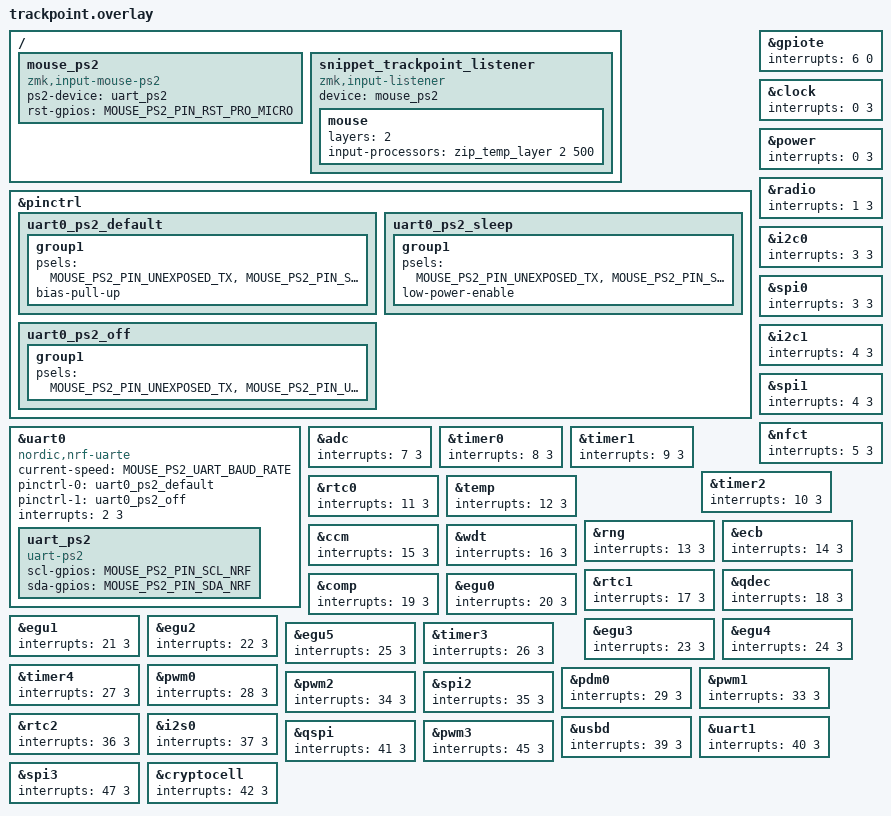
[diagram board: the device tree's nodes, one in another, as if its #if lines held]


#define MOUSE_PS2_DRIVER_UART
#define MOUSE_PS2_PIN_SCL_NRF <&gpio0 14 GPIO_ACTIVE_HIGH>
#define MOUSE_PS2_PIN_SDA_NRF <&gpio0 12 GPIO_ACTIVE_HIGH>
#define MOUSE_PS2_PIN_SDA_PINCTRL <NRF_PSEL(UART_RX, 0, 12)>
// Configure the Power-On-Reset pin

//#define MOUSE_PS2_PIN_RST_PRO_MICRO <&pro_micro 9 GPIO_ACTIVE_HIGH>

// Configure UART BAUD Rate
//
// Convert cycle length in microseconds into baud:
// 1 / PS2_CYCLE_LENGTH * 1000000 =  BAUD
// 1 / 67 * 1000000 = 14,925 BAUD
// Most trackpoints seem to operate at around 14-15kHz.
// Therefore, the most likely values to try are:
//   - 14400 ( 69 us cycle length   /   14.5kHz)
//   -  9600 (100 us cycle length   /   10.0kHz)
//   - 19200 ( 52 us cycle length   /   19kHz)
#define MOUSE_PS2_UART_BAUD_RATE <14400>

// Do NOT change these if you are using a nice!nano (or a clone of it)
#define MOUSE_PS2_PIN_UNEXPOSED_TX <NRF_PSEL(UART_TX, 0, 25)>
#define MOUSE_PS2_PIN_UNEXPOSED_RX <NRF_PSEL(UART_RX, 0, 27)>

#define MOUSE_PS2_DT_PRESENT

&pinctrl {
	uart0_ps2_default: uart0_ps2_default {
		group1 {
			psels = MOUSE_PS2_PIN_UNEXPOSED_TX,
					MOUSE_PS2_PIN_SDA_PINCTRL;
            bias-pull-up;
		};
	};

	// Set this to the same pins as uart0_ps2_default
	uart0_ps2_sleep: uart0_ps2_sleep {
		group1 {
			psels = MOUSE_PS2_PIN_UNEXPOSED_TX,
					MOUSE_PS2_PIN_SDA_PINCTRL;
			low-power-enable;
		};
	};

	uart0_ps2_off: uart0_ps2_off {
		group1 {
			psels = MOUSE_PS2_PIN_UNEXPOSED_TX,
					MOUSE_PS2_PIN_UNEXPOSED_RX;
		};
	};
};


#ifdef MOUSE_PS2_DRIVER_UART

    &uart0 {
       
        compatible = "nordic,nrf-uarte";

        current-speed = MOUSE_PS2_UART_BAUD_RATE;
        pinctrl-0 = <&uart0_ps2_default>;
        pinctrl-1 = <&uart0_ps2_off>;

        pinctrl-names = "default", "sleep";

        uart_ps2: uart_ps2 {
          
            compatible = "uart-ps2";
            scl-gpios = MOUSE_PS2_PIN_SCL_NRF;
            sda-gpios = MOUSE_PS2_PIN_SDA_NRF;
        };
    };

#else

    / {
        gpio_ps2: gpio_ps2 {
            status = "disabled";

            compatible = "gpio-ps2";
            scl-gpios = MOUSE_PS2_PIN_SCL_NRF;
            sda-gpios = MOUSE_PS2_PIN_SDA_NRF;
        };
    };

#endif


/ {
    mouse_ps2: mouse_ps2 {
        compatible = "zmk,input-mouse-ps2";
        
#ifdef MOUSE_PS2_DRIVER_UART
	    ps2-device = <&uart_ps2>;
#else
	    ps2-device = <&gpio_ps2>;
#endif

#ifdef MOUSE_PS2_PIN_RST_PRO_MICRO
        rst-gpios = MOUSE_PS2_PIN_RST_PRO_MICRO;
#endif
    };
};

/{
    snippet_trackpoint_listener: snippet_trackpoint_listener {
        compatible = "zmk,input-listener";
        device = <&mouse_ps2>;
        mouse {
            layers = <2>;
            input-processors = <&zip_temp_layer 2 500>;
        };
    };    
};

&gpiote {
    interrupts = < 6 0 >;
};

&clock {
    interrupts = < 0 3 >;
};

&power {
    interrupts = < 0 3 >;
};

&radio {
    interrupts = < 1 3 >;
};

&uart0 {
    interrupts = < 2 3 >;
};

&i2c0 {
    interrupts = < 3 3 >;
};

&spi0 {
    interrupts = < 3 3 >;
};

&i2c1 {
    interrupts = < 4 3 >;
};

&spi1 {
    interrupts = < 4 3 >;
};

&nfct {
    interrupts = < 5 3 >;
};

&adc {
    interrupts = < 7 3 >;
};

&timer0 {
    interrupts = < 8 3 >;
};

&timer1 {
    interrupts = < 9 3 >;
};

&timer2 {
    interrupts = < 10 3 >;
};

&rtc0 {
    interrupts = < 11 3 >;
};

&temp {
    interrupts = < 12 3 >;
};

&rng {
    interrupts = < 13 3 >;
};

&ecb {
    interrupts = < 14 3 >;
};

&ccm {
    interrupts = < 15 3 >;
};

&wdt {
    interrupts = < 16 3 >;
};

&rtc1 {
    interrupts = < 17 3 >;
};

&qdec {
    interrupts = < 18 3 >;
};

&comp {
    interrupts = < 19 3 >;
};

&egu0 {
    interrupts = < 20 3 >;
};

&egu1 {
    interrupts = < 21 3 >;
};

&egu2 {
    interrupts = < 22 3 >;
};

&egu3 {
    interrupts = < 23 3 >;
};

&egu4 {
    interrupts = < 24 3 >;
};

&egu5 {
    interrupts = < 25 3 >;
};

&timer3 {
    interrupts = < 26 3 >;
};

&timer4 {
    interrupts = < 27 3 >;
};

&pwm0 {
    interrupts = < 28 3 >;
};

&pdm0 {
    interrupts = < 29 3 >;
};

&pwm1 {
    interrupts = < 33 3 >;
};

&pwm2 {
    interrupts = < 34 3 >;
};

&spi2 {
    interrupts = < 35 3 >;
};

&rtc2 {
    interrupts = < 36 3 >;
};

&i2s0 {
    interrupts = < 37 3 >;
};

&usbd {
    interrupts = < 39 3 >;
};

&uart1 {
    interrupts = < 40 3 >;
};

&qspi {
    interrupts = < 41 3 >;
};

&pwm3 {
    interrupts = < 45 3 >;
};

&spi3 {
    interrupts = < 47 3 >;
};

&cryptocell {
    interrupts = < 42 3 >;
};

